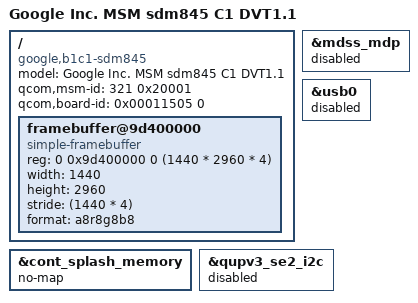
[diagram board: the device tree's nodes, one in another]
/* Copyright (c) 2018 Google, Inc.
 *
 * This software is licensed under the terms of the GNU General Public
 * License version 2, as published by the Free Software Foundation, and
 * may be copied, distributed, and modified under those terms.
 *
 * This program is distributed in the hope that it will be useful,
 * but WITHOUT ANY WARRANTY; without even the implied warranty of
 * MERCHANTABILITY or FITNESS FOR A PARTICULAR PURPOSE.  See the
 * GNU General Public License for more details.
 *
 */

/dts-v1/;
/plugin/;

#include "sdm845-c1-common.dtsi"
#include "sdm845-patherm.dtsi"
#include "sdm845-usbctherm.dtsi"
#include "sdm845-c1-usb-v3.dtsi"
#include "sdm845-c1-audio-cal.dtsi"

/ {
	model = "Google Inc. MSM sdm845 C1 DVT1.1";
	compatible = "google,b1c1-sdm845", "qcom,sdm845";
	qcom,msm-id = <321 0x20001>;
	qcom,board-id = <0x00011505 0>;
};

/* TEMP bring-up: kernel console on the bootloader splash buffer */
/ {
	framebuffer@9d400000 {
		compatible = "simple-framebuffer";
		reg = <0 0x9d400000 0 (1440 * 2960 * 4)>;
		width = <1440>;
		height = <2960>;
		stride = <(1440 * 4)>;
		format = "a8r8g8b8";
		status = "okay";
	};
};

&cont_splash_memory {
	no-map;
};

&mdss_mdp {
	status = "disabled";
};

/* TEMP: dwc3-msm loops in deferred probe; take USB out to see what's next */
&usb0 {
	status = "disabled";
};

/* TEMP: sec_ts probe spins on GSI I2C timeouts and stalls deferred probe */
&qupv3_se2_i2c {
	status = "disabled";
};
